# FSPSYNTH register map
Vendor: SYNTH-Corp; File version: 1.0
Renesas FSP style fixture
CPU: CM33 r0p1, little endian
Registers are 32-bit, access not given, reset 0x0 unless marked. A register's access mark holds for its fields unless they carry their own. Offsets are from the block's base; lines under a group give offsets from that group; [hi:lo] are bit positions; {n}, {i} and the like mark numbered series; 'fields as' and 'values as' point back to an identical list; <NAME> marks a mode.

## Memory map
0x40006000 ICU size 0x400 — Interrupt controller unit
0x40008000 CPSCU size 0x100 — CPU security unit
0x400F3000 TSN size 0x10 — Temperature sensor
0x40169000 GPT320 size 0x100 — General PWM timer 32-bit channel 0

## ICU — Interrupt controller unit
Base 0x40006000
0x00 IELSR0
  [0] IR
0x04 IELSR1
  [0] IR
0x08 IELSR2
0x0C IELSR3

## CPSCU — CPU security unit
Base 0x40008000
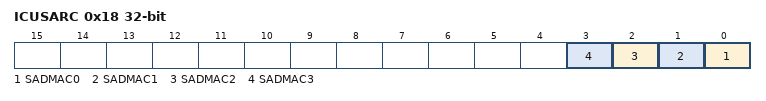
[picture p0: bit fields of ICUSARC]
0x18 ICUSARC — ICU security attribution
  [n] SADMAC{n} (n=0..3)

## GPT320 — General PWM timer 32-bit channel 0
Base 0x40169000
0x00 GTWP — General PWM timer write protection
0x04 GTCR — General PWM timer control

## TSN — Temperature sensor
Base 0x400F3000
0x00 TSCR — Temperature sensor control
